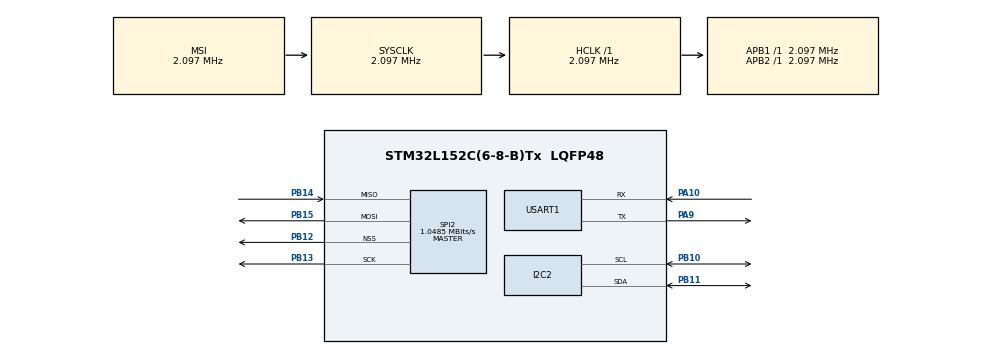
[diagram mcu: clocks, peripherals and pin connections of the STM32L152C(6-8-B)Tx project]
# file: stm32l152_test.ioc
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Mcu.Family=STM32L1
Mcu.Name=STM32L152C(6-8-B)Tx
Mcu.Package=LQFP48
NVIC.PriorityGroup=NVIC_PRIORITYGROUP_4
PA10.Mode=Asynchronous
PA10.Signal=USART1_RX
PA9.Mode=Asynchronous
PA9.Signal=USART1_TX
PB10.Mode=I2C
PB10.Signal=I2C2_SCL
PB11.Mode=I2C
PB11.Signal=I2C2_SDA
PB12.Mode=NSS_Signal_Hard_Output
PB12.Signal=SPI2_NSS
PB13.Mode=Full_Duplex_Master
PB13.Signal=SPI2_SCK
PB14.Mode=Full_Duplex_Master
PB14.Signal=SPI2_MISO
PB15.Mode=Full_Duplex_Master
PB15.Signal=SPI2_MOSI
ProjectManager.HeapSize=0x200
ProjectManager.StackSize=0x400
ProjectManager.TargetToolchain=STM32CubeIDE
RCC.AHBFreq_Value=2097000
RCC.APB1Freq_Value=2097000
RCC.APB2Freq_Value=2097000
RCC.HSE_VALUE=24000000
RCC.HSI_VALUE=16000000
RCC.LSE_VALUE=32768
RCC.MSI_VALUE=2097000
RCC.SYSCLKFreq_VALUE=2097000
RCC.VCOOutputFreq_Value=48000000
SPI2.CalculateBaudRate=1.0485 MBits/s
SPI2.Direction=SPI_DIRECTION_2LINES
SPI2.Mode=SPI_MODE_MASTER
SPI2.VirtualNSS=VM_NSSHARD
SPI2.VirtualType=VM_MASTER
USART1.VirtualMode=VM_ASYNC
board=custom

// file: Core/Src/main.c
/* USER CODE BEGIN Header */
/**
  ******************************************************************************
  * @file           : main.c
  * @brief          : Main program body
  ******************************************************************************
  * @attention
  *
  * Copyright (c) 2021 STMicroelectronics.
  * All rights reserved.
  *
  * This software is licensed under terms that can be found in the LICENSE file
  * in the root directory of this software component.
  * If no LICENSE file comes with this software, it is provided AS-IS.
  *
  ******************************************************************************
  */
/* USER CODE END Header */
#include "main.h"

/* USER CODE BEGIN Includes */
#include "printf.h"
/* USER CODE END Includes */

I2C_HandleTypeDef hi2c2;

SPI_HandleTypeDef hspi2;

UART_HandleTypeDef huart1;

void SystemClock_Config(void);
static void MX_GPIO_Init(void);
static void MX_I2C2_Init(void);
static void MX_SPI2_Init(void);
static void MX_USART1_UART_Init(void);

int main(void)
{

  /* MCU Configuration--------------------------------------------------------*/

  /* Reset of all peripherals, Initializes the Flash interface and the Systick. */
  HAL_Init();

  /* Configure the system clock */
  SystemClock_Config();

  /* Initialize all configured peripherals */
  MX_GPIO_Init();
  MX_I2C2_Init();
  MX_SPI2_Init();
  MX_USART1_UART_Init();

  /* Infinite loop */
  while (1)
  {

    /* USER CODE BEGIN 3 */
	  printf("hello world!\r\n");
	  HAL_Delay(5000);

  }
  /* USER CODE END 3 */
}

void SystemClock_Config(void)
{
  RCC_OscInitTypeDef RCC_OscInitStruct = {0};
  RCC_ClkInitTypeDef RCC_ClkInitStruct = {0};

  /** Configure the main internal regulator output voltage
  */
  __HAL_PWR_VOLTAGESCALING_CONFIG(PWR_REGULATOR_VOLTAGE_SCALE1);
  /** Initializes the RCC Oscillators according to the specified parameters
  * in the RCC_OscInitTypeDef structure.
  */
  RCC_OscInitStruct.OscillatorType = RCC_OSCILLATORTYPE_MSI;
  RCC_OscInitStruct.MSIState = RCC_MSI_ON;
  RCC_OscInitStruct.MSICalibrationValue = 0;
  RCC_OscInitStruct.MSIClockRange = RCC_MSIRANGE_5;
  RCC_OscInitStruct.PLL.PLLState = RCC_PLL_NONE;
  if (HAL_RCC_OscConfig(&RCC_OscInitStruct) != HAL_OK)
  {
    Error_Handler();
  }
  /** Initializes the CPU, AHB and APB buses clocks
  */
  RCC_ClkInitStruct.ClockType = RCC_CLOCKTYPE_HCLK|RCC_CLOCKTYPE_SYSCLK
                              |RCC_CLOCKTYPE_PCLK1|RCC_CLOCKTYPE_PCLK2;
  RCC_ClkInitStruct.SYSCLKSource = RCC_SYSCLKSOURCE_MSI;
  RCC_ClkInitStruct.AHBCLKDivider = RCC_SYSCLK_DIV1;
  RCC_ClkInitStruct.APB1CLKDivider = RCC_HCLK_DIV1;
  RCC_ClkInitStruct.APB2CLKDivider = RCC_HCLK_DIV1;

  if (HAL_RCC_ClockConfig(&RCC_ClkInitStruct, FLASH_LATENCY_0) != HAL_OK)
  {
    Error_Handler();
  }
}

static void MX_I2C2_Init(void)
{

  hi2c2.Instance = I2C2;
  hi2c2.Init.ClockSpeed = 100000;
  hi2c2.Init.DutyCycle = I2C_DUTYCYCLE_2;
  hi2c2.Init.OwnAddress1 = 0;
  hi2c2.Init.AddressingMode = I2C_ADDRESSINGMODE_7BIT;
  hi2c2.Init.DualAddressMode = I2C_DUALADDRESS_DISABLE;
  hi2c2.Init.OwnAddress2 = 0;
  hi2c2.Init.GeneralCallMode = I2C_GENERALCALL_DISABLE;
  hi2c2.Init.NoStretchMode = I2C_NOSTRETCH_DISABLE;
  if (HAL_I2C_Init(&hi2c2) != HAL_OK)
  {
    Error_Handler();
  }

}

static void MX_SPI2_Init(void)
{

  /* SPI2 parameter configuration*/
  hspi2.Instance = SPI2;
  hspi2.Init.Mode = SPI_MODE_MASTER;
  hspi2.Init.Direction = SPI_DIRECTION_2LINES;
  hspi2.Init.DataSize = SPI_DATASIZE_8BIT;
  hspi2.Init.CLKPolarity = SPI_POLARITY_LOW;
  hspi2.Init.CLKPhase = SPI_PHASE_1EDGE;
  hspi2.Init.NSS = SPI_NSS_HARD_OUTPUT;
  hspi2.Init.BaudRatePrescaler = SPI_BAUDRATEPRESCALER_2;
  hspi2.Init.FirstBit = SPI_FIRSTBIT_MSB;
  hspi2.Init.TIMode = SPI_TIMODE_DISABLE;
  hspi2.Init.CRCCalculation = SPI_CRCCALCULATION_DISABLE;
  hspi2.Init.CRCPolynomial = 10;
  if (HAL_SPI_Init(&hspi2) != HAL_OK)
  {
    Error_Handler();
  }

}

static void MX_USART1_UART_Init(void)
{

  huart1.Instance = USART1;
  huart1.Init.BaudRate = 115200;
  huart1.Init.WordLength = UART_WORDLENGTH_8B;
  huart1.Init.StopBits = UART_STOPBITS_1;
  huart1.Init.Parity = UART_PARITY_NONE;
  huart1.Init.Mode = UART_MODE_TX_RX;
  huart1.Init.HwFlowCtl = UART_HWCONTROL_NONE;
  huart1.Init.OverSampling = UART_OVERSAMPLING_16;
  if (HAL_UART_Init(&huart1) != HAL_OK)
  {
    Error_Handler();
  }

}

static void MX_GPIO_Init(void)
{

  /* GPIO Ports Clock Enable */
  __HAL_RCC_GPIOB_CLK_ENABLE();
  __HAL_RCC_GPIOA_CLK_ENABLE();

}

void Error_Handler(void)
{
  __disable_irq();
  while (1)
  {
  }
}
